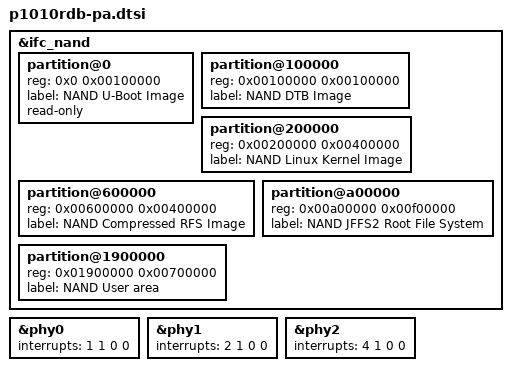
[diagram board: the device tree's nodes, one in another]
/*
 * P1010 RDB Device Tree Source stub (no addresses or top-level ranges)
 *
 * Copyright 2013 Freescale Semiconductor Inc.
 *
 * Redistribution and use in source and binary forms, with or without
 * modification, are permitted provided that the following conditions are met:
 *     * Redistributions of source code must retain the above copyright
 *       notice, this list of conditions and the following disclaimer.
 *     * Redistributions in binary form must reproduce the above copyright
 *       notice, this list of conditions and the following disclaimer in the
 *       documentation and/or other materials provided with the distribution.
 *     * Neither the name of Freescale Semiconductor nor the
 *       names of its contributors may be used to endorse or promote products
 *       derived from this software without specific prior written permission.
 *
 *
 * ALTERNATIVELY, this software may be distributed under the terms of the
 * GNU General Public License ("GPL") as published by the Free Software
 * Foundation, either version 2 of that License or (at your option) any
 * later version.
 *
 * THIS SOFTWARE IS PROVIDED BY Freescale Semiconductor ``AS IS'' AND ANY
 * EXPRESS OR IMPLIED WARRANTIES, INCLUDING, BUT NOT LIMITED TO, THE IMPLIED
 * WARRANTIES OF MERCHANTABILITY AND FITNESS FOR A PARTICULAR PURPOSE ARE
 * DISCLAIMED. IN NO EVENT SHALL Freescale Semiconductor BE LIABLE FOR ANY
 * DIRECT, INDIRECT, INCIDENTAL, SPECIAL, EXEMPLARY, OR CONSEQUENTIAL DAMAGES
 * (INCLUDING, BUT NOT LIMITED TO, PROCUREMENT OF SUBSTITUTE GOODS OR SERVICES;
 * LOSS OF USE, DATA, OR PROFITS; OR BUSINESS INTERRUPTION) HOWEVER CAUSED AND
 * ON ANY THEORY OF LIABILITY, WHETHER IN CONTRACT, STRICT LIABILITY, OR TORT
 * (INCLUDING NEGLIGENCE OR OTHERWISE) ARISING IN ANY WAY OUT OF THE USE OF THIS
 * SOFTWARE, EVEN IF ADVISED OF THE POSSIBILITY OF SUCH DAMAGE.
 */

&ifc_nand {
	partition@0 {
		/* This location must not be altered  */
		/* 1MB for u-boot Bootloader Image */
		reg = <0x0 0x00100000>;
		label = "NAND U-Boot Image";
		read-only;
	};

	partition@100000 {
		/* 1MB for DTB Image */
		reg = <0x00100000 0x00100000>;
		label = "NAND DTB Image";
	};

	partition@200000 {
		/* 4MB for Linux Kernel Image */
		reg = <0x00200000 0x00400000>;
		label = "NAND Linux Kernel Image";
	};

	partition@600000 {
		/* 4MB for Compressed Root file System Image */
		reg = <0x00600000 0x00400000>;
		label = "NAND Compressed RFS Image";
	};

	partition@a00000 {
		/* 15MB for JFFS2 based Root file System */
		reg = <0x00a00000 0x00f00000>;
		label = "NAND JFFS2 Root File System";
	};

	partition@1900000 {
		/* 7MB for User Area */
		reg = <0x01900000 0x00700000>;
		label = "NAND User area";
	};
};

&phy0 {
	interrupts = <1 1 0 0>;
};

&phy1 {
	interrupts = <2 1 0 0>;
};

&phy2 {
	interrupts = <4 1 0 0>;
};
